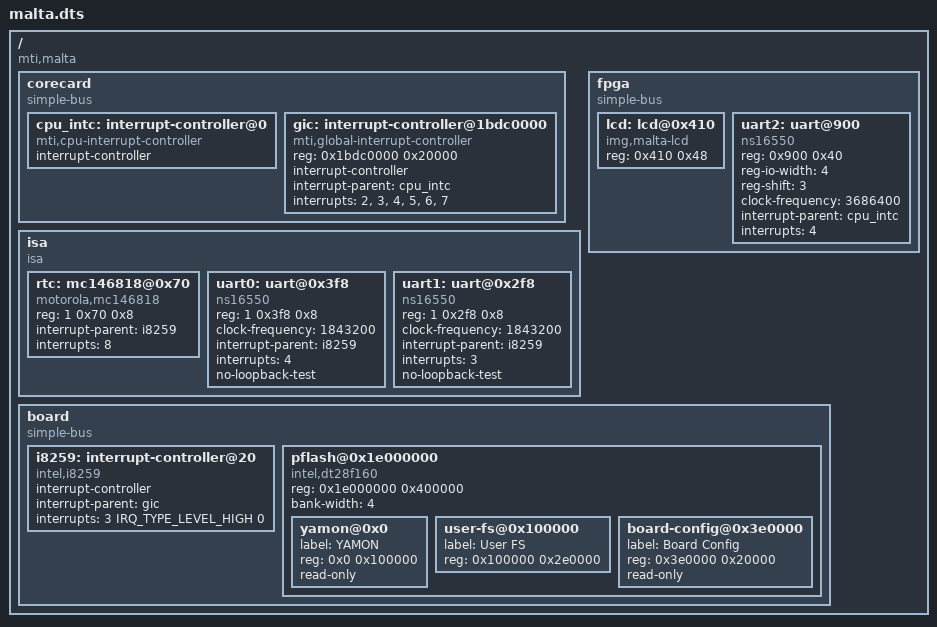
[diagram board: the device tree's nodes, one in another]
/dts-v1/;

#include <dt-bindings/interrupt-controller/irq.h>

/ {
	#address-cells = <1>;
	#size-cells = <1>;
	compatible = "mti,malta";

	corecard {
		compatible = "simple-bus";
		#address-cells = <1>;
		#size-cells = <1>;
		ranges = <>;

		cpu_intc: interrupt-controller@0 {
			compatible = "mti,cpu-interrupt-controller";

			interrupt-controller;
			#interrupt-cells = <1>;
		};

		gic: interrupt-controller@1bdc0000 {
			compatible = "mti,global-interrupt-controller";
			reg = <0x1bdc0000 0x20000>;

			interrupt-controller;
			#interrupt-cells = <3>;

			interrupt-parent = <&cpu_intc>;
			interrupts = <2>, <3>, <4>, <5>, <6>, <7>;
		};
	};

	isa {
		compatible = "isa";
		#address-cells = <2>;
		#size-cells = <1>;
		ranges = <1 0 0 0x1000>;

		rtc: mc146818@0x70 {
			compatible = "motorola,mc146818";
			reg = <1 0x70 0x8>;

			interrupt-parent = <&i8259>;
			interrupts = <8>;
		};

		uart0: uart@0x3f8 {
			compatible = "ns16550";
			reg = <1 0x3f8 0x8>;

			clock-frequency = <1843200>;

			interrupt-parent = <&i8259>;
			interrupts = <4>;

			no-loopback-test;
		};

		uart1: uart@0x2f8 {
			compatible = "ns16550";
			reg = <1 0x2f8 0x8>;

			clock-frequency = <1843200>;

			interrupt-parent = <&i8259>;
			interrupts = <3>;

			no-loopback-test;
		};
	};

	fpga {
		compatible = "simple-bus";
		#address-cells = <1>;
		#size-cells = <1>;
		ranges = <0 0x1f000000 0x100000>;

		lcd: lcd@0x410 {
			compatible = "img,malta-lcd";
			reg = <0x410 0x48>;
		};

		uart2: uart@900 {
			compatible = "ns16550";

			reg = <0x900 0x40>;
			reg-io-width = <4>;
			reg-shift = <3>;

			clock-frequency = <3686400>;

			interrupt-parent = <&cpu_intc>;
			interrupts = <4>;
		};
	};

	board {
		compatible = "simple-bus";
		#address-cells = <1>;
		#size-cells = <1>;
		ranges = <>;

		i8259: interrupt-controller@20 {
			compatible = "intel,i8259";

			interrupt-controller;
			#interrupt-cells = <1>;

			interrupt-parent = <&gic>;
			interrupts = <3 IRQ_TYPE_LEVEL_HIGH 0>;
		};

		pflash@0x1e000000 {
			compatible = "intel,dt28f160", "cfi-flash";
			reg = <0x1e000000 0x400000>;
			bank-width = <4>;
			#address-cells = <1>;
			#size-cells = <1>;

			yamon@0x0 {
				label = "YAMON";
				reg = <0x0 0x100000>;
				read-only;
			};

			user-fs@0x100000 {
				label = "User FS";
				reg = <0x100000 0x2e0000>;
			};

			board-config@0x3e0000 {
				label = "Board Config";
				reg = <0x3e0000 0x20000>;
				read-only;
			};
		};
	};
};
